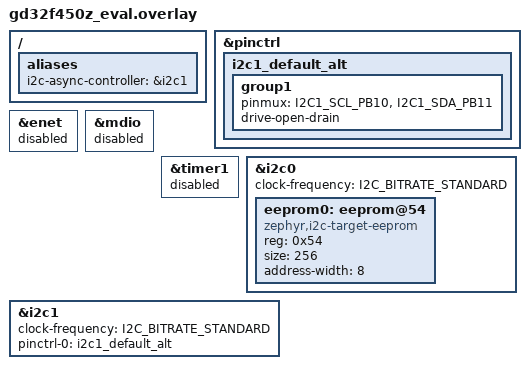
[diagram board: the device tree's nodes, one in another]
/*
 * Copyright (c) 2026 Ylhyra ehf.
 * SPDX-License-Identifier: Apache-2.0
 */

#include <zephyr/dt-bindings/i2c/i2c.h>

/ {
	aliases {
		i2c-async-controller = &i2c1;
	};
};

&pinctrl {
	i2c1_default_alt: i2c1_default_alt {
		group1 {
			pinmux = <I2C1_SCL_PB10>, <I2C1_SDA_PB11>;
			drive-open-drain;
		};
	};
};

&enet {
	status = "disabled";
};

&mdio {
	status = "disabled";
};

&timer1 {
	status = "disabled";
};

&i2c0 {
	clock-frequency = <I2C_BITRATE_STANDARD>;
	/delete-node/ eeprom@50;

	eeprom0: eeprom@54 {
		compatible = "zephyr,i2c-target-eeprom";
		reg = <0x54>;
		size = <256>;
		address-width = <8>;
	};
};

&i2c1 {
	status = "okay";
	clock-frequency = <I2C_BITRATE_STANDARD>;
	pinctrl-0 = <&i2c1_default_alt>;
	pinctrl-names = "default";
};
